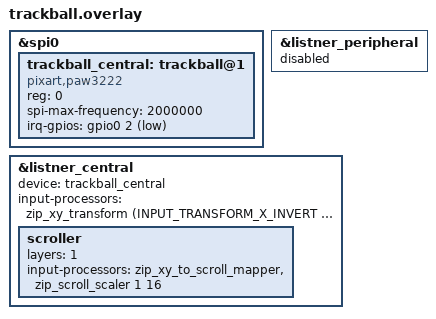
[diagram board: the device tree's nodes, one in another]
&spi0 {
    status = "okay";

    trackball_central: trackball@1 {
        status = "okay";
        compatible = "pixart,paw3222";
        reg = <0>;
        spi-max-frequency = <2000000>;
        irq-gpios = <&gpio0 2 (GPIO_ACTIVE_LOW | GPIO_PULL_UP)>;
    };
};

&listner_peripheral {
    status = "disabled";
};

&listner_central {
    status = "okay";
    device = <&trackball_central>;
    input-processors = 
        <&zip_xy_transform (INPUT_TRANSFORM_X_INVERT | INPUT_TRANSFORM_Y_INVERT)>;

    scroller {
        layers = <1>;
        input-processors = 
            <&zip_xy_to_scroll_mapper>,
            <&zip_scroll_scaler 1 16>;
    };
};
